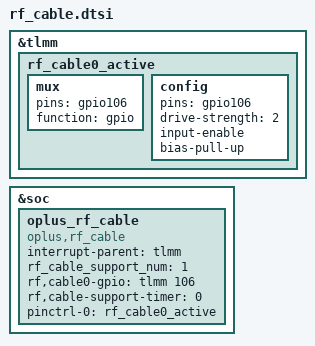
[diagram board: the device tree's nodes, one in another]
&tlmm {
  //#ifdef OPLUS_FEATURE_RF_CABLE_DETECT
  rf_cable0_active: rf_cable0_active {
    mux {
      pins = "gpio106";
      function = "gpio";
    };
    config {
      pins = "gpio106";
      drive-strength = <2>;
      input-enable;
      bias-pull-up;
    };
  };
  //#endif /* OPLUS_FEATURE_RF_CABLE_DETECT */
};

&soc {
  //#ifdef OPLUS_FEATURE_RF_CABLE_DETECT
  oplus_rf_cable {
    compatible = "oplus,rf_cable";
    interrupt-parent = <&tlmm>;
    rf_cable_support_num = <1>;
    rf,cable0-gpio = <&tlmm 106 0>;
    rf,cable-support-timer = <0>;
    pinctrl-names = "rf_cable_active";
    pinctrl-0 = <&rf_cable0_active>;
  };
  //#endif /* OPLUS_FEATURE_RF_CABLE_DETECT */
};
